VERSION ""

NS_ :

BS_:

BU_: GearECU

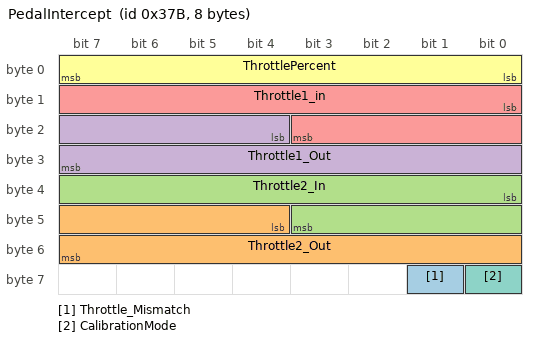
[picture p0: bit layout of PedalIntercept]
BO_ 891 PedalIntercept: 8 GearECU
 SG_ Throttle_Mismatch : 57|1@1+ (1,0) [0|1] "" Vector__XXX
 SG_ Throttle2_Out : 44|12@1+ (2,0) [0|8190] "mV" Vector__XXX
 SG_ Throttle2_In : 32|12@1+ (2,0) [0|8190] "mV" Vector__XXX
 SG_ Throttle1_Out : 20|12@1+ (2,0) [0|8190] "mV" Vector__XXX
 SG_ Throttle1_in : 8|12@1+ (2,0) [0|8190] "mV" Vector__XXX
 SG_ ThrottlePercent : 0|8@1+ (1,0) [0|100] "%" Vector__XXX
 SG_ CalibrationMode : 56|1@1+ (1,0) [0|0] "" Vector__XXX

BA_DEF_ SG_  "GenSigSendType" ENUM  "Cyclic","OnWrite","OnWriteWithRepetition","OnChange","OnChangeWithRepetition","IfActive","IfActiveWithRepetition","NoSigSendType";
BA_DEF_ SG_  "GenSigILSupport" ENUM  "No","Yes";
BA_DEF_ SG_  "GenSigEVName" STRING ;
BA_DEF_ SG_  "SigType" ENUM  "Default","Range","RangeSigned","ASCII","Discrete","Control","ReferencePGN","DTC","StringDelimiter","StringLength","StringLengthControl";
BA_DEF_ BO_  "VFrameFormat" ENUM  "StandardCAN","ExtendedCAN","reserved","J1939PG";
BA_DEF_ BO_  "GenMsgRequestable" INT 0 1;
BA_DEF_ BO_  "GenMsgSendType" ENUM  "cyclic","NotUsed","IfActive","NotUsed","NotUsed","NotUsed","NotUsed","NotUsed","noMsgSendType";
BA_DEF_ BO_  "GenMsgILSupport" ENUM  "No","Yes";
BA_DEF_ BU_  "NmStationAddress" INT 0 255;
BA_DEF_ BU_  "NodeLayerModules" STRING ;
BA_DEF_ BU_  "NmAsrCanMsgReducedTime" INT 0 65535;
BA_DEF_ BU_  "NmAsrNode" ENUM  "no","yes";
BA_DEF_  "ProtocolType" STRING ;
BA_DEF_  "DBName" STRING ;
BA_DEF_  "NmAsrBaseAddress" HEX 0 536870911;
BA_DEF_  "NmAsrCanMsgCycleTime" INT 0 65535;
BA_DEF_  "NmAsrMessageCount" INT 0 256;
BA_DEF_  "NmAsrRepeatMessageTime" INT 0 65535;
BA_DEF_  "NmAsrTimeoutTime" INT 0 65535;
BA_DEF_  "NmAsrWaitBusSleepTime" INT 0 65535;
BA_DEF_  "Baudrate" INT 0 10000000;
BA_DEF_  "BusType" STRING ;
BA_DEF_DEF_  "GenSigSendType" "NoSigSendType";
BA_DEF_DEF_  "GenSigILSupport" "Yes";
BA_DEF_DEF_  "GenSigEVName" "Env@Nodename_@Signame";
BA_DEF_DEF_  "SigType" "Default";
BA_DEF_DEF_  "VFrameFormat" "J1939PG";
BA_DEF_DEF_  "GenMsgRequestable" 1;
BA_DEF_DEF_  "GenMsgSendType" "noMsgSendType";
BA_DEF_DEF_  "GenMsgILSupport" "Yes";
BA_DEF_DEF_  "NmStationAddress" 254;
BA_DEF_DEF_  "NodeLayerModules" "J1939_IL.dll";
BA_DEF_DEF_  "NmAsrCanMsgReducedTime" 50;
BA_DEF_DEF_  "NmAsrNode" "yes";
BA_DEF_DEF_  "ProtocolType" "J1939";
BA_DEF_DEF_  "DBName" "";
BA_DEF_DEF_  "NmAsrBaseAddress" 486506496;
BA_DEF_DEF_  "NmAsrCanMsgCycleTime" 100;
BA_DEF_DEF_  "NmAsrMessageCount" 64;
BA_DEF_DEF_  "NmAsrRepeatMessageTime" 400;
BA_DEF_DEF_  "NmAsrTimeoutTime" 1000;
BA_DEF_DEF_  "NmAsrWaitBusSleepTime" 750;
BA_DEF_DEF_  "Baudrate" 500000;
BA_DEF_DEF_  "BusType" "CAN";
BA_ "ProtocolType" "CAN";
BA_ "DBName" "ZeroEv";
BA_ "NmStationAddress" BU_ GearECU 8;
BA_ "VFrameFormat" BO_ 891 0;
VAL_ 891 Throttle_Mismatch 1 "Yes" 0 "No" ;
VAL_ 891 CalibrationMode 1 "Yes" 0 "No" ;
